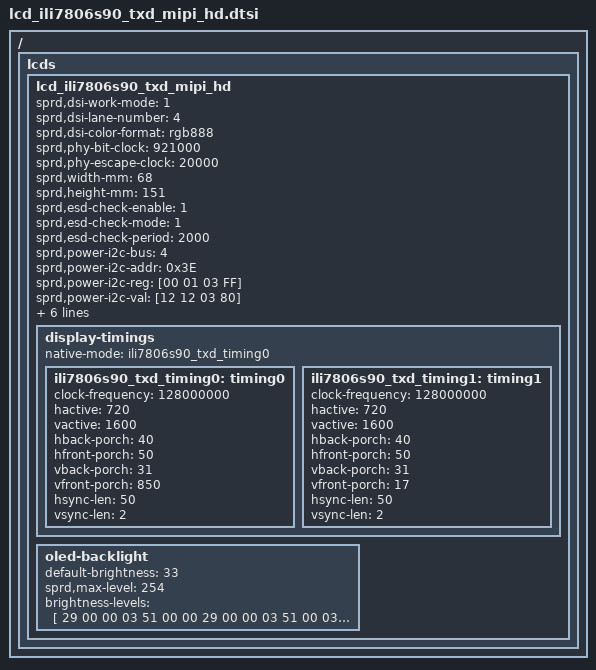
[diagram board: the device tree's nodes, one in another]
/*
 * ili9882n90 tm HD Scaling-Up LCD config dtsi file for spreadtrum
 *
 * Copyright (C) 2018, Spreadtrum Communications Inc.
 *
 * SPDX-License-Identifier: (GPL-2.0+ OR MIT)
 */

/ {
	fragment {
		target-path = "/";
		__overlay__ {
			lcds {
				lcd_ili7806s90_txd_mipi_hd: lcd_ili7806s90_txd_mipi_hd {

					sprd,dsi-work-mode = <1>; /* video burst mode*/
					sprd,dsi-lane-number = <4>;
					sprd,dsi-color-format = "rgb888";

					sprd,phy-bit-clock = <921000>;	/* kbps */
					sprd,phy-escape-clock = <20000>;/* kHz */

					sprd,width-mm = <68>;
					sprd,height-mm = <151>;

					sprd,esd-check-enable = <1>;
					sprd,esd-check-mode = <1>;
					sprd,esd-check-period = <2000>;
					//sprd,esd-check-register = <0xA>;
					//sprd,esd-check-value = <0x9c>;

					sprd,power-i2c-bus = <4>;
        				sprd,power-i2c-addr = <0x3E>;
        				/*sprd,power-i2c-speed = <400000>;*/
        				sprd,power-i2c-reg = [00 01 03 FF];
					sprd,power-i2c-val = [12 12 03 80];

					sprd,reset-on-sequence = <1 10>, <0 10>, <1 100>;
					sprd,reset-off-sequence = <1 10>;

					//sprd,use-dcs-write;

					sprd,initial-command = [
						29 00 00 04 FF 78 07 00
                        13 00 00 02 35 00
						29 00 00 03 68 04 01
                        13 00 00 02 53 2C
                        13 00 00 02 55 01
                        03 78 00 01 11
                        29 00 00 04 FF 78 07 02
                        13 00 00 02 01 B4
                        29 00 00 04 FF 78 07 00
                        03 14 00 01 29
						];

					sprd,sleep-in-command = [
						03 32 00 01 28
						03 96 00 01 10
						];

					display-timings {
						native-mode = <&ili7806s90_txd_timing0>;

						ili7806s90_txd_timing0: timing0 {
								clock-frequency = <128000000>;
								hactive = <720>;
								vactive = <1600>;
								hback-porch = <40>;
								hfront-porch = <50>;
								vback-porch = <31>;
								vfront-porch = <850>;
								hsync-len = <50>;
								vsync-len = <2>;
						};

						ili7806s90_txd_timing1: timing1 {
								clock-frequency = <128000000>;
								hactive = <720>;
								vactive = <1600>;
								hback-porch = <40>;
								hfront-porch = <50>;
								vback-porch = <31>;
								vfront-porch = <17>;
								hsync-len = <50>;
								vsync-len = <2>;
						};
					};

					oled-backlight {			
						default-brightness = <33>;	
						sprd,max-level = <254>;
						brightness-levels = [				
							29 00 00 03 51 00 00
							29 00 00 03 51 00 03
							29 00 00 03 51 00 09
							29 00 00 03 51 00 0F
							29 00 00 03 51 00 15
							29 00 00 03 51 00 1B
							29 00 00 03 51 00 21
							29 00 00 03 51 00 27
							29 00 00 03 51 00 2C
							29 00 00 03 51 00 32
							29 00 00 03 51 00 38
							29 00 00 03 51 00 3E
							29 00 00 03 51 00 44
							29 00 00 03 51 00 4A
							29 00 00 03 51 00 50
							29 00 00 03 51 00 55
							29 00 00 03 51 00 5B
							29 00 00 03 51 00 61
							29 00 00 03 51 00 67
							29 00 00 03 51 00 6D
							29 00 00 03 51 00 73
							29 00 00 03 51 00 78
							29 00 00 03 51 00 7E
							29 00 00 03 51 00 84
							29 00 00 03 51 00 8A
							29 00 00 03 51 00 90
							29 00 00 03 51 00 96
							29 00 00 03 51 00 9C
							29 00 00 03 51 00 A1
							29 00 00 03 51 00 A7
							29 00 00 03 51 00 AD
							29 00 00 03 51 00 B3
							29 00 00 03 51 00 B9
							29 00 00 03 51 00 BF
							29 00 00 03 51 00 C5
							29 00 00 03 51 00 CA
							29 00 00 03 51 00 D0
							29 00 00 03 51 00 D6
							29 00 00 03 51 00 DC
							29 00 00 03 51 00 E2
							29 00 00 03 51 00 E8
							29 00 00 03 51 00 ED
							29 00 00 03 51 00 F3
							29 00 00 03 51 00 F9
							29 00 00 03 51 00 FF
							29 00 00 03 51 01 05
							29 00 00 03 51 01 0B
							29 00 00 03 51 01 11
							29 00 00 03 51 01 16
							29 00 00 03 51 01 1C
							29 00 00 03 51 01 22
							29 00 00 03 51 01 28
							29 00 00 03 51 01 2E
							29 00 00 03 51 01 34
							29 00 00 03 51 01 3A
							29 00 00 03 51 01 3F
							29 00 00 03 51 01 45
							29 00 00 03 51 01 4B
							29 00 00 03 51 01 51
							29 00 00 03 51 01 57
							29 00 00 03 51 01 5D
							29 00 00 03 51 01 62
							29 00 00 03 51 01 68
							29 00 00 03 51 01 6E
							29 00 00 03 51 01 74
							29 00 00 03 51 01 7A
							29 00 00 03 51 01 80
							29 00 00 03 51 01 86
							29 00 00 03 51 01 8B
							29 00 00 03 51 01 91
							29 00 00 03 51 01 97
							29 00 00 03 51 01 9D
							29 00 00 03 51 01 A3
							29 00 00 03 51 01 A9
							29 00 00 03 51 01 AF
							29 00 00 03 51 01 B4
							29 00 00 03 51 01 BA
							29 00 00 03 51 01 C0
							29 00 00 03 51 01 C6
							29 00 00 03 51 01 CC
							29 00 00 03 51 01 D2
							29 00 00 03 51 01 D7
							29 00 00 03 51 01 DD
							29 00 00 03 51 01 E3
							29 00 00 03 51 01 E9
							29 00 00 03 51 01 EF
							29 00 00 03 51 01 F5
							29 00 00 03 51 01 FB
							29 00 00 03 51 02 00
							29 00 00 03 51 02 06
							29 00 00 03 51 02 0C
							29 00 00 03 51 02 12
							29 00 00 03 51 02 18
							29 00 00 03 51 02 1E
							29 00 00 03 51 02 24
							29 00 00 03 51 02 29
							29 00 00 03 51 02 2F
							29 00 00 03 51 02 35
							29 00 00 03 51 02 3B
							29 00 00 03 51 02 41
							29 00 00 03 51 02 47
							29 00 00 03 51 02 4C
							29 00 00 03 51 02 52
							29 00 00 03 51 02 58
							29 00 00 03 51 02 5E
							29 00 00 03 51 02 64
							29 00 00 03 51 02 6A
							29 00 00 03 51 02 70
							29 00 00 03 51 02 75
							29 00 00 03 51 02 7B
							29 00 00 03 51 02 81
							29 00 00 03 51 02 87
							29 00 00 03 51 02 8D
							29 00 00 03 51 02 93
							29 00 00 03 51 02 99
							29 00 00 03 51 02 9E
							29 00 00 03 51 02 A4
							29 00 00 03 51 02 AA
							29 00 00 03 51 02 B0
							29 00 00 03 51 02 B6
							29 00 00 03 51 02 BC
							29 00 00 03 51 02 C1
							29 00 00 03 51 02 C7
							29 00 00 03 51 02 CD
							29 00 00 03 51 02 D3
							29 00 00 03 51 02 D9
							29 00 00 03 51 02 DF
							29 00 00 03 51 02 E5
							29 00 00 03 51 02 EA
							29 00 00 03 51 02 F0
							29 00 00 03 51 02 F6
							29 00 00 03 51 02 FC
							29 00 00 03 51 03 02
							29 00 00 03 51 03 08
							29 00 00 03 51 03 0E
							29 00 00 03 51 03 13
							29 00 00 03 51 03 19
							29 00 00 03 51 03 1F
							29 00 00 03 51 03 25
							29 00 00 03 51 03 2B
							29 00 00 03 51 03 31
							29 00 00 03 51 03 36
							29 00 00 03 51 03 3C
							29 00 00 03 51 03 42
							29 00 00 03 51 03 48
							29 00 00 03 51 03 4E
							29 00 00 03 51 03 54
							29 00 00 03 51 03 5A
							29 00 00 03 51 03 5F
							29 00 00 03 51 03 65
							29 00 00 03 51 03 6B
							29 00 00 03 51 03 71
							29 00 00 03 51 03 77
							29 00 00 03 51 03 7D
							29 00 00 03 51 03 83
							29 00 00 03 51 03 88
							29 00 00 03 51 03 8E
							29 00 00 03 51 03 94
							29 00 00 03 51 03 9A
							29 00 00 03 51 03 A0
							29 00 00 03 51 03 A6
							29 00 00 03 51 03 AB
							29 00 00 03 51 03 B1
							29 00 00 03 51 03 B7
							29 00 00 03 51 03 BD
							29 00 00 03 51 03 C3
							29 00 00 03 51 03 C9
							29 00 00 03 51 03 CF
							29 00 00 03 51 03 D4
							29 00 00 03 51 03 DA
							29 00 00 03 51 03 E0
							29 00 00 03 51 03 E6
							29 00 00 03 51 03 EC
							29 00 00 03 51 03 F2
							29 00 00 03 51 03 F8
							29 00 00 03 51 03 FD
							29 00 00 03 51 04 03
							29 00 00 03 51 04 09
							29 00 00 03 51 04 0F
							29 00 00 03 51 04 15
							29 00 00 03 51 04 1B
							29 00 00 03 51 04 20
							29 00 00 03 51 04 26
							29 00 00 03 51 04 2C
							29 00 00 03 51 04 32
							29 00 00 03 51 04 38
							29 00 00 03 51 04 3E
							29 00 00 03 51 04 44
							29 00 00 03 51 04 49
							29 00 00 03 51 04 4F
							29 00 00 03 51 04 55
							29 00 00 03 51 04 5B
							29 00 00 03 51 04 61
							29 00 00 03 51 04 67
							29 00 00 03 51 04 6D
							29 00 00 03 51 04 72
							29 00 00 03 51 04 78
							29 00 00 03 51 04 7E
							29 00 00 03 51 04 84
							29 00 00 03 51 04 8A
							29 00 00 03 51 04 90
							29 00 00 03 51 04 95
							29 00 00 03 51 04 9B
							29 00 00 03 51 04 A1
							29 00 00 03 51 04 A7
							29 00 00 03 51 04 AD
							29 00 00 03 51 04 B3
							29 00 00 03 51 04 B9
							29 00 00 03 51 04 BE
							29 00 00 03 51 04 C4
							29 00 00 03 51 04 CA
							29 00 00 03 51 04 D0
							29 00 00 03 51 04 D6
							29 00 00 03 51 04 DC
							29 00 00 03 51 04 E2
							29 00 00 03 51 04 E7
							29 00 00 03 51 04 ED
							29 00 00 03 51 04 F3
							29 00 00 03 51 04 F9
							29 00 00 03 51 04 FF
							29 00 00 03 51 05 05
							29 00 00 03 51 05 0A
							29 00 00 03 51 05 10
							29 00 00 03 51 05 16
							29 00 00 03 51 05 1C
							29 00 00 03 51 05 22
							29 00 00 03 51 05 28
							29 00 00 03 51 05 2E
							29 00 00 03 51 05 33
							29 00 00 03 51 05 39
							29 00 00 03 51 05 3F
							29 00 00 03 51 05 45
							29 00 00 03 51 05 4B
							29 00 00 03 51 05 51
							29 00 00 03 51 05 57
							29 00 00 03 51 05 5C
							29 00 00 03 51 05 62
							29 00 00 03 51 05 68
							29 00 00 03 51 05 6E
							29 00 00 03 51 05 74
							29 00 00 03 51 05 7A
							29 00 00 03 51 05 7F
							29 00 00 03 51 05 85
							29 00 00 03 51 05 8B
							29 00 00 03 51 05 91
							29 00 00 03 51 05 97
							29 00 00 03 51 05 9D
							29 00 00 03 51 05 A3
							29 00 00 03 51 05 A8
							29 00 00 03 51 05 AE
							29 00 00 03 51 05 B4
							29 00 00 03 51 05 BA
							29 00 00 03 51 05 C0
							29 00 00 03 51 05 C6
							29 00 00 03 51 05 CC
						];
					};
				};
			};
		};
	};
};
